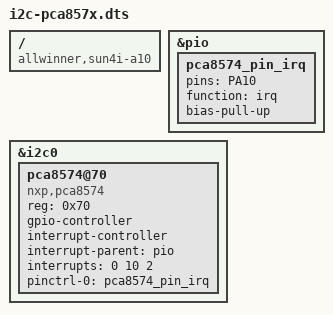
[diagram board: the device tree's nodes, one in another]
/dts-v1/;
/plugin/;

/ {
	compatible = "allwinner,sun4i-a10", "allwinner,sun7i-a20", "allwinner,sun50i-a64", "allwinner,sun50i-h5";

	fragment@0 {
		/* This fragment is required only if using interrupts */
		target = <&pio>;
		__overlay__ {
			pca8574_pin_irq: pca8574_pin_irq {
				pins = "PA10";
				function = "irq";
				bias-pull-up;
			};
		};
	};

	fragment@1 {
		target = <&i2c0>;
		__overlay__ {
			#address-cells = <1>;
			#size-cells = <0>;
			pca8574@70 {
				compatible = "nxp,pca8574";
				reg = <0x70>;
				status = "okay";
				gpio-controller;
				#gpio-cells = <2>;
				/* Below are optional properties for supporting interrupts */
				interrupt-controller;
				#interrupt-cells = <2>;
				interrupt-parent = <&pio>;
				interrupts = <0 10 2>; /* PA10 IRQ_TYPE_EDGE_FALLING */
				pinctrl-names = "default";
				pinctrl-0 = <&pca8574_pin_irq>;
			};
		};
	};
};
